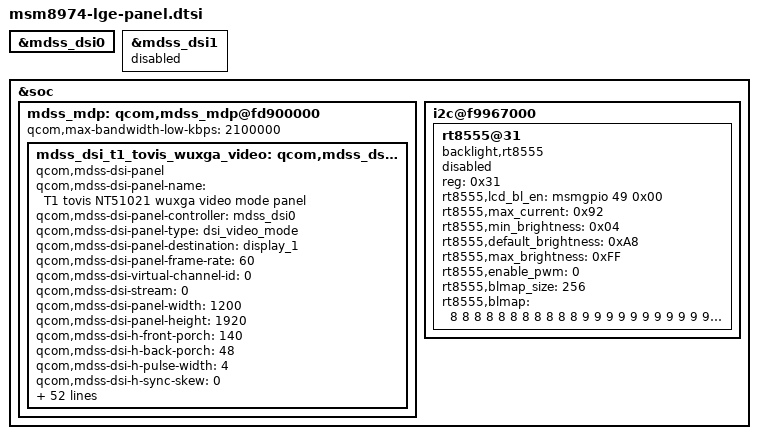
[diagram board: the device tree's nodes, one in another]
/* Copyright (c) 2013, LGE Electronics. All rights reserved.
 *
 * This program is free software; you can redistribute it and/or modify
 * it under the terms of the GNU General Public License version 2 and
 * only version 2 as published by the Free Software Foundation.
 *
 * This program is distributed in the hope that it will be useful,
 * but WITHOUT ANY WARRANTY; without even the implied warranty of
 * MERCHANTABILITY or FITNESS FOR A PARTICULAR PURPOSE.  See the
 * GNU General Public License for more details.
 */

/*---------------------------------------------------------------------------
 * This file is autogenerated file using gcdb parser. Please do not edit it.
 * Update input XML file to add a new entry or update variable in this file
 * VERSION = "1.0"
 *---------------------------------------------------------------------------*/

&mdss_dsi0 {
	/delete-node/ qcom,platform-supply-entry1;
};

&mdss_dsi1 {
	status = "disable";
};

&soc {
	mdss_mdp: qcom,mdss_mdp@fd900000 {
		qcom,max-bandwidth-low-kbps = <2100000>;
	};
};

&mdss_mdp {
		/delete-property/ qcom,mdss-ad-off;

mdss_dsi_t1_tovis_wuxga_video: qcom,mdss_dsi_tovis_nt51021_t1_wuxga_video {
		compatible = "qcom,mdss-dsi-panel";
		qcom,mdss-dsi-panel-name = "T1 tovis NT51021 wuxga video mode panel";
		qcom,mdss-dsi-panel-controller = <&mdss_dsi0>;
		qcom,mdss-dsi-panel-type = "dsi_video_mode";
		qcom,mdss-dsi-panel-destination = "display_1";
		qcom,mdss-dsi-panel-frame-rate = <60>;
		qcom,mdss-dsi-virtual-channel-id = <0>;
		qcom,mdss-dsi-stream = <0>;
		qcom,mdss-dsi-panel-width = <1200>;
		qcom,mdss-dsi-panel-height = <1920>;
		qcom,mdss-dsi-h-front-porch = <140>;
		qcom,mdss-dsi-h-back-porch = <48>;
		qcom,mdss-dsi-h-pulse-width = <4>;
		qcom,mdss-dsi-h-sync-skew = <0>;
		qcom,mdss-dsi-v-back-porch = <14>;
		qcom,mdss-dsi-v-front-porch = <16>;
		qcom,mdss-dsi-v-pulse-width = <1>;
		qcom,mdss-dsi-h-left-border = <0>;
		qcom,mdss-dsi-h-right-border = <0>;
		qcom,mdss-dsi-v-top-border = <0>;
		qcom,mdss-dsi-v-bottom-border = <0>;
		qcom,mdss-dsi-bpp = <24>;
		qcom,mdss-dsi-color-order = "rgb_swap_rgb";
		qcom,mdss-dsi-underflow-color = <0xff>;
		qcom,mdss-dsi-border-color = <0>;
		qcom,mdss-dsi-reset-sequence = <1 5>;
		qcom,cont-splash-enabled;
		qcom,mdss-dsi-lane-hs = <1>;
		qcom,mdss-dsi-on-command = [
		15 01 00 00 00 00 02 83 00
		15 01 00 00 00 00 02 84 00
		15 01 00 00 00 00 02 97 C0  // Set terminal resistor to 75 ohm
		15 01 00 00 00 00 02 8C 8E  // Change HAVDD , V1/V14 , Gamma to register control
		15 01 00 00 00 00 02 FA 12  // Set HAVDD = 4.8V
		15 01 00 00 01 00 02 FD 1B  // Set V1 = 9.4V , V14 = 0.2V
		15 01 00 00 00 00 02 C4 12  // Set STV rising timing
		15 01 00 00 00 00 02 C5 77  // Set STV falling timing
		15 01 00 00 00 00 02 C6 12  // Set GCLK rising timing
		15 01 00 00 00 00 02 C7 77  // Set GCLK falling timing
		15 01 00 00 00 00 02 83 AA
		15 01 00 00 00 00 02 84 11
		15 01 00 00 00 00 02 A9 4B  // Set MIPI Rx ability to solve data loss
		15 01 00 00 00 00 02 A0 36  // Set Slave IC of MIPI D0/D1 lane delay 100ps
		15 01 00 00 00 00 02 A1 3F  // Set Slave IC of MIPI D2/D3 lane delay 150ps
		15 01 00 00 00 00 02 A2 2D  // Set Master IC of MIPI D0/D1 lane delay 50ps
		15 01 00 00 00 00 02 A3 36  // Set Master IC of MIPI D2/D3 lane delay 100ps
		//----R Gamma Register----
		15 01 00 00 00 00 02 83 AA
		15 01 00 00 00 00 02 84 11
		15 01 00 00 00 00 02 C0 12
		15 01 00 00 00 00 02 C1 12
		15 01 00 00 00 00 02 C2 25
		15 01 00 00 00 00 02 C3 36
		15 01 00 00 00 00 02 C4 42
		15 01 00 00 00 00 02 C5 4B
		15 01 00 00 00 00 02 C6 57
		15 01 00 00 00 00 02 C7 5B
		15 01 00 00 00 00 02 C8 66
		15 01 00 00 00 00 02 C9 DB
		15 01 00 00 00 00 02 CA DF
		15 01 00 00 00 00 02 CB F5
		15 01 00 00 00 00 02 CC FE
		15 01 00 00 00 00 02 CD FC
		15 01 00 00 00 00 02 CE F7
		15 01 00 00 00 00 02 CF F9
		15 01 00 00 00 00 02 D0 FB
		15 01 00 00 00 00 02 D1 0A
		15 01 00 00 00 00 02 D2 1F
		15 01 00 00 00 00 02 D3 40
		15 01 00 00 00 00 02 D4 4A
		15 01 00 00 00 00 02 D5 AE
		15 01 00 00 00 00 02 D6 B0
		15 01 00 00 00 00 02 D7 BB
		15 01 00 00 00 00 02 D8 C5
		15 01 00 00 00 00 02 D9 CE
		15 01 00 00 00 00 02 DA D8
		15 01 00 00 00 00 02 DB E7
		15 01 00 00 00 00 02 DC F0
		15 01 00 00 00 00 02 DD FF
		15 01 00 00 00 00 02 DE 00
		15 01 00 00 00 00 02 DF 2F
		15 01 00 00 00 00 02 E0 12
		15 01 00 00 00 00 02 E1 12
		15 01 00 00 00 00 02 E2 25
		15 01 00 00 00 00 02 E3 36
		15 01 00 00 00 00 02 E4 42
		15 01 00 00 00 00 02 E5 4B
		15 01 00 00 00 00 02 E6 57
		15 01 00 00 00 00 02 E7 5B
		15 01 00 00 00 00 02 E8 66
		15 01 00 00 00 00 02 E9 DB
		15 01 00 00 00 00 02 EA DF
		15 01 00 00 00 00 02 EB F5
		15 01 00 00 00 00 02 EC FE
		15 01 00 00 00 00 02 ED FC
		15 01 00 00 00 00 02 EE F7
		15 01 00 00 00 00 02 EF F9
		15 01 00 00 00 00 02 F0 FB
		15 01 00 00 00 00 02 F1 0A
		15 01 00 00 00 00 02 F2 1F
		15 01 00 00 00 00 02 F3 40
		15 01 00 00 00 00 02 F4 4A
		15 01 00 00 00 00 02 F5 AE
		15 01 00 00 00 00 02 F6 B0
		15 01 00 00 00 00 02 F7 BB
		15 01 00 00 00 00 02 F8 C5
		15 01 00 00 00 00 02 F9 CE
		15 01 00 00 00 00 02 FA D8
		15 01 00 00 00 00 02 FB E7
		15 01 00 00 00 00 02 FC F0
		15 01 00 00 00 00 02 FD FF
		15 01 00 00 00 00 02 FE 00
		15 01 00 00 00 00 02 FF 2F
		//----G Gamma Register----
		15 01 00 00 00 00 02 83 BB
		15 01 00 00 00 00 02 84 22
		15 01 00 00 00 00 02 C0 12
		15 01 00 00 00 00 02 C1 12
		15 01 00 00 00 00 02 C2 25
		15 01 00 00 00 00 02 C3 36
		15 01 00 00 00 00 02 C4 42
		15 01 00 00 00 00 02 C5 4B
		15 01 00 00 00 00 02 C6 57
		15 01 00 00 00 00 02 C7 5B
		15 01 00 00 00 00 02 C8 66
		15 01 00 00 00 00 02 C9 DB
		15 01 00 00 00 00 02 CA DF
		15 01 00 00 00 00 02 CB F5
		15 01 00 00 00 00 02 CC FE
		15 01 00 00 00 00 02 CD FC
		15 01 00 00 00 00 02 CE F7
		15 01 00 00 00 00 02 CF F9
		15 01 00 00 00 00 02 D0 FB
		15 01 00 00 00 00 02 D1 0A
		15 01 00 00 00 00 02 D2 1F
		15 01 00 00 00 00 02 D3 40
		15 01 00 00 00 00 02 D4 4A
		15 01 00 00 00 00 02 D5 AE
		15 01 00 00 00 00 02 D6 B0
		15 01 00 00 00 00 02 D7 BB
		15 01 00 00 00 00 02 D8 C5
		15 01 00 00 00 00 02 D9 CE
		15 01 00 00 00 00 02 DA D8
		15 01 00 00 00 00 02 DB E7
		15 01 00 00 00 00 02 DC F0
		15 01 00 00 00 00 02 DD FF
		15 01 00 00 00 00 02 DE 00
		15 01 00 00 00 00 02 DF 2F
		15 01 00 00 00 00 02 E0 12
		15 01 00 00 00 00 02 E1 12
		15 01 00 00 00 00 02 E2 25
		15 01 00 00 00 00 02 E3 36
		15 01 00 00 00 00 02 E4 42
		15 01 00 00 00 00 02 E5 4B
		15 01 00 00 00 00 02 E6 57
		15 01 00 00 00 00 02 E7 5B
		15 01 00 00 00 00 02 E8 66
		15 01 00 00 00 00 02 E9 DB
		15 01 00 00 00 00 02 EA DF
		15 01 00 00 00 00 02 EB F5
		15 01 00 00 00 00 02 EC FE
		15 01 00 00 00 00 02 ED FC
		15 01 00 00 00 00 02 EE F7
		15 01 00 00 00 00 02 EF F9
		15 01 00 00 00 00 02 F0 FB
		15 01 00 00 00 00 02 F1 0A
		15 01 00 00 00 00 02 F2 1F
		15 01 00 00 00 00 02 F3 40
		15 01 00 00 00 00 02 F4 4A
		15 01 00 00 00 00 02 F5 AE
		15 01 00 00 00 00 02 F6 B0
		15 01 00 00 00 00 02 F7 BB
		15 01 00 00 00 00 02 F8 C5
		15 01 00 00 00 00 02 F9 CE
		15 01 00 00 00 00 02 FA D8
		15 01 00 00 00 00 02 FB E7
		15 01 00 00 00 00 02 FC F0
		15 01 00 00 00 00 02 FD FF
		15 01 00 00 00 00 02 FE 00
		15 01 00 00 00 00 02 FF 2F
		//----B Gamma Register----
		15 01 00 00 00 00 02 83 CC
		15 01 00 00 00 00 02 84 33
		15 01 00 00 00 00 02 C0 12
		15 01 00 00 00 00 02 C1 12
		15 01 00 00 00 00 02 C2 25
		15 01 00 00 00 00 02 C3 36
		15 01 00 00 00 00 02 C4 42
		15 01 00 00 00 00 02 C5 4B
		15 01 00 00 00 00 02 C6 57
		15 01 00 00 00 00 02 C7 5B
		15 01 00 00 00 00 02 C8 66
		15 01 00 00 00 00 02 C9 DB
		15 01 00 00 00 00 02 CA DF
		15 01 00 00 00 00 02 CB F5
		15 01 00 00 00 00 02 CC FE
		15 01 00 00 00 00 02 CD FC
		15 01 00 00 00 00 02 CE F7
		15 01 00 00 00 00 02 CF F9
		15 01 00 00 00 00 02 D0 FB
		15 01 00 00 00 00 02 D1 0A
		15 01 00 00 00 00 02 D2 1F
		15 01 00 00 00 00 02 D3 40
		15 01 00 00 00 00 02 D4 4A
		15 01 00 00 00 00 02 D5 AE
		15 01 00 00 00 00 02 D6 B0
		15 01 00 00 00 00 02 D7 BB
		15 01 00 00 00 00 02 D8 C5
		15 01 00 00 00 00 02 D9 CE
		15 01 00 00 00 00 02 DA D8
		15 01 00 00 00 00 02 DB E7
		15 01 00 00 00 00 02 DC F0
		15 01 00 00 00 00 02 DD FF
		15 01 00 00 00 00 02 DE 00
		15 01 00 00 00 00 02 DF 2F
		15 01 00 00 00 00 02 E0 12
		15 01 00 00 00 00 02 E1 12
		15 01 00 00 00 00 02 E2 25
		15 01 00 00 00 00 02 E3 36
		15 01 00 00 00 00 02 E4 42
		15 01 00 00 00 00 02 E5 4B
		15 01 00 00 00 00 02 E6 57
		15 01 00 00 00 00 02 E7 5B
		15 01 00 00 00 00 02 E8 66
		15 01 00 00 00 00 02 E9 DB
		15 01 00 00 00 00 02 EA DF
		15 01 00 00 00 00 02 EB F5
		15 01 00 00 00 00 02 EC FE
		15 01 00 00 00 00 02 ED FC
		15 01 00 00 00 00 02 EE F7
		15 01 00 00 00 00 02 EF F9
		15 01 00 00 00 00 02 F0 FB
		15 01 00 00 00 00 02 F1 0A
		15 01 00 00 00 00 02 F2 1F
		15 01 00 00 00 00 02 F3 40
		15 01 00 00 00 00 02 F4 4A
		15 01 00 00 00 00 02 F5 AE
		15 01 00 00 00 00 02 F6 B0
		15 01 00 00 00 00 02 F7 BB
		15 01 00 00 00 00 02 F8 C5
		15 01 00 00 00 00 02 F9 CE
		15 01 00 00 00 00 02 FA D8
		15 01 00 00 00 00 02 FB E7
		15 01 00 00 00 00 02 FC F0
		15 01 00 00 00 00 02 FD FF
		15 01 00 00 00 00 02 FE 00
		15 01 00 00 00 00 02 FF 2F
		];

		qcom,mdss-dsi-off-command = [
		05 01 00 00 64 00 02 10 00
		];

		qcom,panel-charging-time-on-command = [
		15 01 00 00 00 00 02 83 00
		15 01 00 00 00 00 02 84 00
		15 01 00 00 00 00 02 C7 A6
		];

		qcom,panel-charging-time-off-command = [
		15 01 00 00 00 00 02 83 00
		15 01 00 00 00 00 02 84 00
		15 01 00 00 00 00 02 C7 77
		];

		qcom,panel-reader-mode-initial-on-command = [
		15 01 00 00 00 00 02 83 00
		15 01 00 00 00 00 02 84 00
		15 01 00 00 00 00 02 97 C0
		15 01 00 00 00 00 02 8C 8E
		15 01 00 00 00 00 02 FA 12
		15 01 00 00 01 00 02 FD 1B
		15 01 00 00 00 00 02 C4 12
		15 01 00 00 00 00 02 C5 77
		15 01 00 00 00 00 02 C6 12
		15 01 00 00 00 00 02 C7 77
		15 01 00 00 00 00 02 83 AA
		15 01 00 00 00 00 02 84 11
		15 00 00 00 00 00 02 A9 4B
		15 01 00 00 00 00 02 A0 36
		15 01 00 00 00 00 02 A1 3F
		15 01 00 00 00 00 02 A2 2D
		15 01 00 00 00 00 02 A3 36
		//----R Gamma Register----
		15 01 00 00 00 00 02 83 AA
		15 01 00 00 00 00 02 84 11
		15 01 00 00 00 00 02 C0 00
		15 01 00 00 00 00 02 C1 0A
		15 01 00 00 00 00 02 C2 0F
		15 01 00 00 00 00 02 C3 17
		15 01 00 00 00 00 02 C4 21
		15 01 00 00 00 00 02 C5 31
		15 01 00 00 00 00 02 C6 42
		15 01 00 00 00 00 02 C7 4D
		15 01 00 00 00 00 02 C8 55
		15 01 00 00 00 00 02 C9 B0
		15 01 00 00 00 00 02 CA B8
		15 01 00 00 00 00 02 CB D4
		15 01 00 00 00 00 02 CC E2
		15 01 00 00 00 00 02 CD EA
		15 01 00 00 00 00 02 CE ED
		15 01 00 00 00 00 02 CF EF
		15 01 00 00 00 00 02 D0 F7
		15 01 00 00 00 00 02 D1 0E
		15 01 00 00 00 00 02 D2 24
		15 01 00 00 00 00 02 D3 46
		15 01 00 00 00 00 02 D4 50
		15 01 00 00 00 00 02 D5 B1
		15 01 00 00 00 00 02 D6 B8
		15 01 00 00 00 00 02 D7 C0
		15 01 00 00 00 00 02 D8 C9
		15 01 00 00 00 00 02 D9 D2
		15 01 00 00 00 00 02 DA DD
		15 01 00 00 00 00 02 DB E9
		15 01 00 00 00 00 02 DC F7
		15 01 00 00 00 00 02 DD FF
		15 01 00 00 00 00 02 DE 00
		15 01 00 00 00 00 02 DF 0F
		15 01 00 00 00 00 02 E0 00
		15 01 00 00 00 00 02 E1 0A
		15 01 00 00 00 00 02 E2 0F
		15 01 00 00 00 00 02 E3 17
		15 01 00 00 00 00 02 E4 21
		15 01 00 00 00 00 02 E5 31
		15 01 00 00 00 00 02 E6 42
		15 01 00 00 00 00 02 E7 4D
		15 01 00 00 00 00 02 E8 55
		15 01 00 00 00 00 02 E9 B0
		15 01 00 00 00 00 02 EA B8
		15 01 00 00 00 00 02 EB D4
		15 01 00 00 00 00 02 EC E2
		15 01 00 00 00 00 02 ED EA
		15 01 00 00 00 00 02 EE ED
		15 01 00 00 00 00 02 EF EF
		15 01 00 00 00 00 02 F0 F7
		15 01 00 00 00 00 02 F1 0E
		15 01 00 00 00 00 02 F2 24
		15 01 00 00 00 00 02 F3 46
		15 01 00 00 00 00 02 F4 50
		15 01 00 00 00 00 02 F5 B1
		15 01 00 00 00 00 02 F6 B8
		15 01 00 00 00 00 02 F7 C0
		15 01 00 00 00 00 02 F8 C9
		15 01 00 00 00 00 02 F9 D2
		15 01 00 00 00 00 02 FA DD
		15 01 00 00 00 00 02 FB E9
		15 01 00 00 00 00 02 FC F7
		15 01 00 00 00 00 02 FD FF
		15 01 00 00 00 00 02 FE 00
		15 01 00 00 00 00 02 FF 0F
		//----G Gamma Register----
		15 01 00 00 00 00 02 83 BB
		15 01 00 00 00 00 02 84 22
		15 01 00 00 00 00 02 C0 00
		15 01 00 00 00 00 02 C1 0A
		15 01 00 00 00 00 02 C2 10
		15 01 00 00 00 00 02 C3 18
		15 01 00 00 00 00 02 C4 21
		15 01 00 00 00 00 02 C5 2A
		15 01 00 00 00 00 02 C6 34
		15 01 00 00 00 00 02 C7 3D
		15 01 00 00 00 00 02 C8 45
		15 01 00 00 00 00 02 C9 9A
		15 01 00 00 00 00 02 CA A6
		15 01 00 00 00 00 02 CB C0
		15 01 00 00 00 00 02 CC CB
		15 01 00 00 00 00 02 CD D2
		15 01 00 00 00 00 02 CE D2
		15 01 00 00 00 00 02 CF D4
		15 01 00 00 00 00 02 D0 D4
		15 01 00 00 00 00 02 D1 DE
		15 01 00 00 00 00 02 D2 EA
		15 01 00 00 00 00 02 D3 FB
		15 01 00 00 00 00 02 D4 F7
		15 01 00 00 00 00 02 D5 7B
		15 01 00 00 00 00 02 D6 7F
		15 01 00 00 00 00 02 D7 83
		15 01 00 00 00 00 02 D8 87
		15 01 00 00 00 00 02 D9 8C
		15 01 00 00 00 00 02 DA 90
		15 01 00 00 00 00 02 DB 95
		15 01 00 00 00 00 02 DC 9A
		15 01 00 00 00 00 02 DD 9D
		15 01 00 00 00 00 02 DE 00
		15 01 00 00 00 00 02 DF 00
		15 01 00 00 00 00 02 E0 00
		15 01 00 00 00 00 02 E1 0A
		15 01 00 00 00 00 02 E2 10
		15 01 00 00 00 00 02 E3 18
		15 01 00 00 00 00 02 E4 21
		15 01 00 00 00 00 02 E5 2A
		15 01 00 00 00 00 02 E6 34
		15 01 00 00 00 00 02 E7 3D
		15 01 00 00 00 00 02 E8 45
		15 01 00 00 00 00 02 E9 9A
		15 01 00 00 00 00 02 EA A6
		15 01 00 00 00 00 02 EB C0
		15 01 00 00 00 00 02 EC CB
		15 01 00 00 00 00 02 ED D2
		15 01 00 00 00 00 02 EE D2
		15 01 00 00 00 00 02 EF D4
		15 01 00 00 00 00 02 F0 D4
		15 01 00 00 00 00 02 F1 DE
		15 01 00 00 00 00 02 F2 EA
		15 01 00 00 00 00 02 F3 FB
		15 01 00 00 00 00 02 F4 F7
		15 01 00 00 00 00 02 F5 7B
		15 01 00 00 00 00 02 F6 7F
		15 01 00 00 00 00 02 F7 83
		15 01 00 00 00 00 02 F8 87
		15 01 00 00 00 00 02 F9 8C
		15 01 00 00 00 00 02 FA 90
		15 01 00 00 00 00 02 FB 95
		15 01 00 00 00 00 02 FC 9A
		15 01 00 00 00 00 02 FD 9D
		15 01 00 00 00 00 02 FE 00
		15 01 00 00 00 00 02 FF 00
		//----B Gamma Register----
		15 01 00 00 00 00 02 83 CC
		15 01 00 00 00 00 02 84 33
		15 01 00 00 00 00 02 C0 00
		15 01 00 00 00 00 02 C1 06
		15 01 00 00 00 00 02 C2 09
		15 01 00 00 00 00 02 C3 12
		15 01 00 00 00 00 02 C4 17
		15 01 00 00 00 00 02 C5 18
		15 01 00 00 00 00 02 C6 1A
		15 01 00 00 00 00 02 C7 1C
		15 01 00 00 00 00 02 C8 24
		15 01 00 00 00 00 02 C9 79
		15 01 00 00 00 00 02 CA 8F
		15 01 00 00 00 00 02 CB B1
		15 01 00 00 00 00 02 CC BF
		15 01 00 00 00 00 02 CD C4
		15 01 00 00 00 00 02 CE C2
		15 01 00 00 00 00 02 CF C4
		15 01 00 00 00 00 02 D0 C1
		15 01 00 00 00 00 02 D1 C3
		15 01 00 00 00 00 02 D2 C9
		15 01 00 00 00 00 02 D3 D2
		15 01 00 00 00 00 02 D4 C9
		15 01 00 00 00 00 02 D5 60
		15 01 00 00 00 00 02 D6 63
		15 01 00 00 00 00 02 D7 66
		15 01 00 00 00 00 02 D8 6A
		15 01 00 00 00 00 02 D9 6D
		15 01 00 00 00 00 02 DA 70
		15 01 00 00 00 00 02 DB 74
		15 01 00 00 00 00 02 DC 77
		15 01 00 00 00 00 02 DD 79
		15 01 00 00 00 00 02 DE 00
		15 01 00 00 00 00 02 DF 00
		15 01 00 00 00 00 02 E0 00
		15 01 00 00 00 00 02 E1 06
		15 01 00 00 00 00 02 E2 09
		15 01 00 00 00 00 02 E3 12
		15 01 00 00 00 00 02 E4 17
		15 01 00 00 00 00 02 E5 18
		15 01 00 00 00 00 02 E6 1A
		15 01 00 00 00 00 02 E7 1C
		15 01 00 00 00 00 02 E8 24
		15 01 00 00 00 00 02 E9 79
		15 01 00 00 00 00 02 EA 8F
		15 01 00 00 00 00 02 EB B1
		15 01 00 00 00 00 02 EC BF
		15 01 00 00 00 00 02 ED C4
		15 01 00 00 00 00 02 EE C2
		15 01 00 00 00 00 02 EF C4
		15 01 00 00 00 00 02 F0 C1
		15 01 00 00 00 00 02 F1 C3
		15 01 00 00 00 00 02 F2 C9
		15 01 00 00 00 00 02 F3 D2
		15 01 00 00 00 00 02 F4 C9
		15 01 00 00 00 00 02 F5 60
		15 01 00 00 00 00 02 F6 63
		15 01 00 00 00 00 02 F7 66
		15 01 00 00 00 00 02 F8 6A
		15 01 00 00 00 00 02 F9 6D
		15 01 00 00 00 00 02 FA 70
		15 01 00 00 00 00 02 FB 74
		15 01 00 00 00 00 02 FC 77
		15 01 00 00 00 00 02 FD 79
		15 01 00 00 00 00 02 FE 00
		15 01 00 00 00 00 02 FF 00
		];

		qcom,panel-reader-mode-on-command = [
		//----B Gamma Register----
		15 00 00 00 00 00 02 83 CC
		15 00 00 00 00 00 02 84 33
		15 00 00 00 00 00 02 C0 00
		15 00 00 00 00 00 02 C1 06
		15 00 00 00 00 00 02 C2 09
		15 00 00 00 00 00 02 C3 12
		15 00 00 00 00 00 02 C4 17
		15 00 00 00 00 00 02 C5 18
		15 00 00 00 00 00 02 C6 1A
		15 00 00 00 00 00 02 C7 1C
		15 00 00 00 00 00 02 C8 24
		15 00 00 00 00 00 02 C9 79
		15 00 00 00 00 00 02 CA 8F
		15 00 00 00 00 00 02 CB B1
		15 00 00 00 00 00 02 CC BF
		15 01 00 00 00 00 02 CD C4
		15 00 00 00 00 00 02 CE C2
		15 00 00 00 00 00 02 CF C4
		15 00 00 00 00 00 02 D0 C1
		15 00 00 00 00 00 02 D1 C3
		15 00 00 00 00 00 02 D2 C9
		15 00 00 00 00 00 02 D3 D2
		15 00 00 00 00 00 02 D4 C9
		15 00 00 00 00 00 02 D5 60
		15 00 00 00 00 00 02 D6 63
		15 00 00 00 00 00 02 D7 66
		15 00 00 00 00 00 02 D8 6A
		15 00 00 00 00 00 02 D9 6D
		15 00 00 00 00 00 02 DA 70
		15 00 00 00 00 00 02 DB 74
		15 00 00 00 00 00 02 DC 77
		15 00 00 00 00 00 02 DD 79
		15 00 00 00 00 00 02 DE 00
		15 00 00 00 00 00 02 DF 00
		15 00 00 00 00 00 02 E0 00
		15 01 00 00 00 00 02 E1 06
		15 00 00 00 00 00 02 E2 09
		15 00 00 00 00 00 02 E3 12
		15 00 00 00 00 00 02 E4 17
		15 00 00 00 00 00 02 E5 18
		15 00 00 00 00 00 02 E6 1A
		15 00 00 00 00 00 02 E7 1C
		15 00 00 00 00 00 02 E8 24
		15 00 00 00 00 00 02 E9 79
		15 00 00 00 00 00 02 EA 8F
		15 00 00 00 00 00 02 EB B1
		15 00 00 00 00 00 02 EC BF
		15 00 00 00 00 00 02 ED C4
		15 00 00 00 00 00 02 EE C2
		15 00 00 00 00 00 02 EF C4
		15 00 00 00 00 00 02 F0 C1
		15 00 00 00 00 00 02 F1 C3
		15 00 00 00 00 00 02 F2 C9
		15 00 00 00 00 00 02 F3 D2
		15 00 00 00 00 00 02 F4 C9
		15 01 00 00 00 00 02 F5 60
		15 00 00 00 00 00 02 F6 63
		15 00 00 00 00 00 02 F7 66
		15 00 00 00 00 00 02 F8 6A
		15 00 00 00 00 00 02 F9 6D
		15 00 00 00 00 00 02 FA 70
		15 00 00 00 00 00 02 FB 74
		15 00 00 00 00 00 02 FC 77
		15 00 00 00 00 00 02 FD 79
		15 00 00 00 00 00 02 FE 00
		15 00 00 00 00 00 02 FF 00
		//----G Gamma Register----
		15 00 00 00 00 00 02 83 BB
		15 01 00 00 00 00 02 84 22
		15 00 00 00 00 00 02 C0 00
		15 00 00 00 00 00 02 C1 0A
		15 00 00 00 00 00 02 C2 10
		15 00 00 00 00 00 02 C3 18
		15 00 00 00 00 00 02 C4 21
		15 00 00 00 00 00 02 C5 2A
		15 00 00 00 00 00 02 C6 34
		15 00 00 00 00 00 02 C7 3D
		15 00 00 00 00 00 02 C8 45
		15 00 00 00 00 00 02 C9 9A
		15 01 00 00 00 00 02 CA A6
		15 00 00 00 00 00 02 CB C0
		15 00 00 00 00 00 02 CC CB
		15 00 00 00 00 00 02 CD D2
		15 00 00 00 00 00 02 CE D2
		15 00 00 00 00 00 02 CF D4
		15 00 00 00 00 00 02 D0 D4
		15 00 00 00 00 00 02 D1 DE
		15 00 00 00 00 00 02 D2 EA
		15 00 00 00 00 00 02 D3 FB
		15 00 00 00 00 00 02 D4 F7
		15 00 00 00 00 00 02 D5 7B
		15 00 00 00 00 00 02 D6 7F
		15 00 00 00 00 00 02 D7 83
		15 00 00 00 00 00 02 D8 87
		15 00 00 00 00 00 02 D9 8C
		15 00 00 00 00 00 02 DA 90
		15 00 00 00 00 00 02 DB 95
		15 00 00 00 00 00 02 DC 9A
		15 00 00 00 00 00 02 DD 9D
		15 00 00 00 00 00 02 DE 00
		15 00 00 00 00 00 02 DF 00
		15 00 00 00 00 00 02 E0 00
		15 00 00 00 00 00 02 E1 0A
		15 01 00 00 00 00 02 E2 10
		15 00 00 00 00 00 02 E3 18
		15 00 00 00 00 00 02 E4 21
		15 00 00 00 00 00 02 E5 2A
		15 00 00 00 00 00 02 E6 34
		15 00 00 00 00 00 02 E7 3D
		15 00 00 00 00 00 02 E8 45
		15 00 00 00 00 00 02 E9 9A
		15 00 00 00 00 00 02 EA A6
		15 00 00 00 00 00 02 EB C0
		15 01 00 00 00 00 02 EC CB
		15 00 00 00 00 00 02 ED D2
		15 00 00 00 00 00 02 EE D2
		15 00 00 00 00 00 02 EF D4
		15 00 00 00 00 00 02 F0 D4
		15 00 00 00 00 00 02 F1 DE
		15 00 00 00 00 00 02 F2 EA
		15 00 00 00 00 00 02 F3 FB
		15 00 00 00 00 00 02 F4 F7
		15 00 00 00 00 00 02 F5 7B
		15 00 00 00 00 00 02 F6 7F
		15 00 00 00 00 00 02 F7 83
		15 00 00 00 00 00 02 F8 87
		15 00 00 00 00 00 02 F9 8C
		15 00 00 00 00 00 02 FA 90
		15 00 00 00 00 00 02 FB 95
		15 00 00 00 00 00 02 FC 9A
		15 00 00 00 00 00 02 FD 9D
		15 00 00 00 00 00 02 FE 00
		15 00 00 00 00 00 02 FF 00
		//----R Gamma Register----
		15 00 00 00 00 00 02 83 AA
		15 01 00 00 00 00 02 84 11
		15 00 00 00 00 00 02 C0 00
		15 00 00 00 00 00 02 C1 0A
		15 00 00 00 00 00 02 C2 0F
		15 00 00 00 00 00 02 C3 17
		15 00 00 00 00 00 02 C4 21
		15 00 00 00 00 00 02 C5 31
		15 00 00 00 00 00 02 C6 42
		15 00 00 00 00 00 02 C7 4D
		15 00 00 00 00 00 02 C8 55
		15 00 00 00 00 00 02 C9 B0
		15 00 00 00 00 00 02 CA B8
		15 00 00 00 00 00 02 CB D4
		15 00 00 00 00 00 02 CC E2
		15 00 00 00 00 00 02 CD EA
		15 00 00 00 00 00 02 CE ED
		15 00 00 00 00 00 02 CF EF
		15 00 00 00 00 00 02 D0 F7
		15 00 00 00 00 00 02 D1 0E
		15 00 00 00 00 00 02 D2 24
		15 00 00 00 00 00 02 D3 46
		15 00 00 00 00 00 02 D4 50
		15 00 00 00 00 00 02 D5 B1
		15 00 00 00 00 00 02 D6 B8
		15 01 00 00 00 00 02 D7 C0
		15 00 00 00 00 00 02 D8 C9
		15 00 00 00 00 00 02 D9 D2
		15 00 00 00 00 00 02 DA DD
		15 00 00 00 00 00 02 DB E9
		15 00 00 00 00 00 02 DC F7
		15 00 00 00 00 00 02 DD FF
		15 00 00 00 00 00 02 DE 00
		15 00 00 00 00 00 02 DF 0F
		15 00 00 00 00 00 02 E0 00
		15 00 00 00 00 00 02 E1 0A
		15 00 00 00 00 00 02 E2 0F
		15 00 00 00 00 00 02 E3 17
		15 00 00 00 00 00 02 E4 21
		15 00 00 00 00 00 02 E5 31
		15 00 00 00 00 00 02 E6 42
		15 00 00 00 00 00 02 E7 4D
		15 00 00 00 00 00 02 E8 55
		15 00 00 00 00 00 02 E9 B0
		15 00 00 00 00 00 02 EA B8
		15 01 00 00 00 00 02 EB D4
		15 00 00 00 00 00 02 EC E2
		15 00 00 00 00 00 02 ED EA
		15 00 00 00 00 00 02 EE ED
		15 00 00 00 00 00 02 EF EF
		15 00 00 00 00 00 02 F0 F7
		15 00 00 00 00 00 02 F1 0E
		15 00 00 00 00 00 02 F2 24
		15 00 00 00 00 00 02 F3 46
		15 00 00 00 00 00 02 F4 50
		15 00 00 00 00 00 02 F5 B1
		15 00 00 00 00 00 02 F6 B8
		15 00 00 00 00 00 02 F7 C0
		15 00 00 00 00 00 02 F8 C9
		15 00 00 00 00 00 02 F9 D2
		15 00 00 00 00 00 02 FA DD
		15 00 00 00 00 00 02 FB E9
		15 00 00 00 00 00 02 FC F7
		15 00 00 00 00 00 02 FD FF
		15 00 00 00 00 00 02 FE 00
		15 01 00 00 00 00 02 FF 0F
		];

		qcom,panel-reader-mode-off-command = [
		//----B Gamma Register----
		15 00 00 00 00 00 02 83 CC
		15 00 00 00 00 00 02 84 33
		15 00 00 00 00 00 02 C0 12
		15 00 00 00 00 00 02 C1 12
		15 00 00 00 00 00 02 C2 25
		15 00 00 00 00 00 02 C3 36
		15 00 00 00 00 00 02 C4 42
		15 00 00 00 00 00 02 C5 4B
		15 00 00 00 00 00 02 C6 57
		15 00 00 00 00 00 02 C7 5B
		15 00 00 00 00 00 02 C8 66
		15 00 00 00 00 00 02 C9 DB
		15 00 00 00 00 00 02 CA DF
		15 00 00 00 00 00 02 CB F5
		15 00 00 00 00 00 02 CC FE
		15 00 00 00 00 00 02 CD FC
		15 00 00 00 00 00 02 CE F7
		15 00 00 00 00 00 02 CF F9
		15 00 00 00 00 00 02 D0 FB
		15 01 00 00 00 00 02 D1 0A
		15 00 00 00 00 00 02 D2 1F
		15 00 00 00 00 00 02 D3 40
		15 00 00 00 00 00 02 D4 4A
		15 00 00 00 00 00 02 D5 AE
		15 00 00 00 00 00 02 D6 B0
		15 00 00 00 00 00 02 D7 BB
		15 00 00 00 00 00 02 D8 C5
		15 00 00 00 00 00 02 D9 CE
		15 00 00 00 00 00 02 DA D8
		15 00 00 00 00 00 02 DB E7
		15 01 00 00 00 00 02 DC F0
		15 00 00 00 00 00 02 DD FF
		15 00 00 00 00 00 02 DE 00
		15 00 00 00 00 00 02 DF 2F
		15 00 00 00 00 00 02 E0 12
		15 00 00 00 00 00 02 E1 12
		15 00 00 00 00 00 02 E2 25
		15 00 00 00 00 00 02 E3 36
		15 00 00 00 00 00 02 E4 42
		15 00 00 00 00 00 02 E5 4B
		15 00 00 00 00 00 02 E6 57
		15 00 00 00 00 00 02 E7 5B
		15 00 00 00 00 00 02 E8 66
		15 00 00 00 00 00 02 E9 DB
		15 00 00 00 00 00 02 EA DF
		15 00 00 00 00 00 02 EB F5
		15 00 00 00 00 00 02 EC FE
		15 00 00 00 00 00 02 ED FC
		15 00 00 00 00 00 02 EE F7
		15 00 00 00 00 00 02 EF F9
		15 00 00 00 00 00 02 F0 FB
		15 01 00 00 00 00 02 F1 0A
		15 00 00 00 00 00 02 F2 1F
		15 00 00 00 00 00 02 F3 40
		15 00 00 00 00 00 02 F4 4A
		15 00 00 00 00 00 02 F5 AE
		15 00 00 00 00 00 02 F6 B0
		15 00 00 00 00 00 02 F7 BB
		15 00 00 00 00 00 02 F8 C5
		15 00 00 00 00 00 02 F9 CE
		15 00 00 00 00 00 02 FA D8
		15 00 00 00 00 00 02 FB E7
		15 00 00 00 00 00 02 FC F0
		15 00 00 00 00 00 02 FD FF
		15 00 00 00 00 00 02 FE 00
		15 00 00 00 00 00 02 FF 2F
		//----G Gamma Register----
		15 00 00 00 00 00 02 83 BB
		15 01 00 00 00 00 02 84 22
		15 00 00 00 00 00 02 C0 12
		15 00 00 00 00 00 02 C1 12
		15 00 00 00 00 00 02 C2 25
		15 00 00 00 00 00 02 C3 36
		15 00 00 00 00 00 02 C4 42
		15 00 00 00 00 00 02 C5 4B
		15 00 00 00 00 00 02 C6 57
		15 00 00 00 00 00 02 C7 5B
		15 00 00 00 00 00 02 C8 66
		15 00 00 00 00 00 02 C9 DB
		15 00 00 00 00 00 02 CA DF
		15 00 00 00 00 00 02 CB F5
		15 00 00 00 00 00 02 CC FE
		15 00 00 00 00 00 02 CD FC
		15 00 00 00 00 00 02 CE F7
		15 00 00 00 00 00 02 CF F9
		15 01 00 00 00 00 02 D0 FB
		15 00 00 00 00 00 02 D1 0A
		15 00 00 00 00 00 02 D2 1F
		15 00 00 00 00 00 02 D3 40
		15 00 00 00 00 00 02 D4 4A
		15 00 00 00 00 00 02 D5 AE
		15 00 00 00 00 00 02 D6 B0
		15 00 00 00 00 00 02 D7 BB
		15 00 00 00 00 00 02 D8 C5
		15 00 00 00 00 00 02 D9 CE
		15 00 00 00 00 00 02 DA D8
		15 00 00 00 00 00 02 DB E7
		15 00 00 00 00 00 02 DC F0
		15 00 00 00 00 00 02 DD FF
		15 00 00 00 00 00 02 DE 00
		15 00 00 00 00 00 02 DF 2F
		15 00 00 00 00 00 02 E0 12
		15 00 00 00 00 00 02 E1 12
		15 00 00 00 00 00 02 E2 25
		15 00 00 00 00 00 02 E3 36
		15 00 00 00 00 00 02 E4 42
		15 00 00 00 00 00 02 E5 4B
		15 00 00 00 00 00 02 E6 57
		15 00 00 00 00 00 02 E7 5B
		15 00 00 00 00 00 02 E8 66
		15 00 00 00 00 00 02 E9 DB
		15 01 00 00 00 00 02 EA DF
		15 00 00 00 00 00 02 EB F5
		15 00 00 00 00 00 02 EC FE
		15 00 00 00 00 00 02 ED FC
		15 00 00 00 00 00 02 EE F7
		15 00 00 00 00 00 02 EF F9
		15 00 00 00 00 00 02 F0 FB
		15 00 00 00 00 00 02 F1 0A
		15 00 00 00 00 00 02 F2 1F
		15 00 00 00 00 00 02 F3 40
		15 00 00 00 00 00 02 F4 4A
		15 00 00 00 00 00 02 F5 AE
		15 00 00 00 00 00 02 F6 B0
		15 00 00 00 00 00 02 F7 BB
		15 00 00 00 00 00 02 F8 C5
		15 00 00 00 00 00 02 F9 CE
		15 00 00 00 00 00 02 FA D8
		15 00 00 00 00 00 02 FB E7
		15 00 00 00 00 00 02 FC F0
		15 00 00 00 00 00 02 FD FF
		15 00 00 00 00 00 02 FE 00
		15 01 00 00 00 00 02 FF 2F
		//----R Gamma Register----
		15 00 00 00 00 00 02 83 AA
		15 00 00 00 00 00 02 84 11
		15 00 00 00 00 00 02 C0 12
		15 00 00 00 00 00 02 C1 12
		15 00 00 00 00 00 02 C2 25
		15 00 00 00 00 00 02 C3 36
		15 00 00 00 00 00 02 C4 42
		15 00 00 00 00 00 02 C5 4B
		15 00 00 00 00 00 02 C6 57
		15 00 00 00 00 00 02 C7 5B
		15 00 00 00 00 00 02 C8 66
		15 00 00 00 00 00 02 C9 DB
		15 00 00 00 00 00 02 CA DF
		15 00 00 00 00 00 02 CB F5
		15 00 00 00 00 00 02 CC FE
		15 00 00 00 00 00 02 CD FC
		15 00 00 00 00 00 02 CE F7
		15 00 00 00 00 00 02 CF F9
		15 00 00 00 00 00 02 D0 FB
		15 01 00 00 00 00 02 D1 0A
		15 00 00 00 00 00 02 D2 1F
		15 00 00 00 00 00 02 D3 40
		15 00 00 00 00 00 02 D4 4A
		15 00 00 00 00 00 02 D5 AE
		15 00 00 00 00 00 02 D6 B0
		15 00 00 00 00 00 02 D7 BB
		15 00 00 00 00 00 02 D8 C5
		15 00 00 00 00 00 02 D9 CE
		15 00 00 00 00 00 02 DA D8
		15 00 00 00 00 00 02 DB E7
		15 01 00 00 00 00 02 DC F0
		15 00 00 00 00 00 02 DD FF
		15 00 00 00 00 00 02 DE 00
		15 00 00 00 00 00 02 DF 2F
		15 00 00 00 00 00 02 E0 12
		15 00 00 00 00 00 02 E1 12
		15 00 00 00 00 00 02 E2 25
		15 00 00 00 00 00 02 E3 36
		15 00 00 00 00 00 02 E4 42
		15 00 00 00 00 00 02 E5 4B
		15 00 00 00 00 00 02 E6 57
		15 00 00 00 00 00 02 E7 5B
		15 00 00 00 00 00 02 E8 66
		15 00 00 00 00 00 02 E9 DB
		15 00 00 00 00 00 02 EA DF
		15 00 00 00 00 00 02 EB F5
		15 00 00 00 00 00 02 EC FE
		15 00 00 00 00 00 02 ED FC
		15 00 00 00 00 00 02 EE F7
		15 00 00 00 00 00 02 EF F9
		15 00 00 00 00 00 02 F0 FB
		15 01 00 00 00 00 02 F1 0A
		15 00 00 00 00 00 02 F2 1F
		15 00 00 00 00 00 02 F3 40
		15 00 00 00 00 00 02 F4 4A
		15 00 00 00 00 00 02 F5 AE
		15 00 00 00 00 00 02 F6 B0
		15 00 00 00 00 00 02 F7 BB
		15 00 00 00 00 00 02 F8 C5
		15 00 00 00 00 00 02 F9 CE
		15 00 00 00 00 00 02 FA D8
		15 00 00 00 00 00 02 FB E7
		15 00 00 00 00 00 02 FC F0
		15 00 00 00 00 00 02 FD FF
		15 00 00 00 00 00 02 FE 00
		15 01 00 00 00 00 02 FF 2F
		];

		qcom,mdss-dsi-on-command-state = "dsi_lp_mode";
		qcom,mdss-dsi-off-command-state = "dsi_hs_mode";
		qcom,mdss-pan-physical-width-dimension = <135>;
		qcom,mdss-pan-physical-height-dimension = <216>;
		qcom,mdss-dsi-h-sync-pulse = <0>;
		qcom,mdss-dsi-traffic-mode = "non_burst_sync_event";
		qcom,mdss-dsi-lane-map = "lane_map_0123";
		qcom,mdss-dsi-bllp-eof-power-mode;
		qcom,mdss-dsi-bllp-power-mode;
		qcom,mdss-dsi-lane-0-state;
		qcom,mdss-dsi-lane-1-state;
		qcom,mdss-dsi-lane-2-state;
		qcom,mdss-dsi-lane-3-state;
		qcom,mdss-dsi-panel-timings = [F2 4B 34 00 70 82 3C 50 4A 03 04 00];
		qcom,mdss-dsi-t-clk-post = <0x02>;
		qcom,mdss-dsi-t-clk-pre = <0x31>;
		qcom,mdss-dsi-bl-min-level = <1>;
		qcom,mdss-dsi-bl-max-level = <255>;
		qcom,mdss-dsi-dma-trigger = "trigger_sw";
		qcom,mdss-dsi-mdp-trigger = "none";
		qcom,mdss-dsi-bl-pmic-control-type = "bl_others";
		qcom,off-cmds-dsi-state = "dsi_hs_mode";
	};
};

&soc {
	i2c@f9967000 {
		rt8555@31 {
			compatible = "backlight,rt8555";
			status = "disabled";
			reg = <0x31>;
			rt8555,lcd_bl_en = <&msmgpio 49 0x00>;
			rt8555,max_current = <0x92>;
			rt8555,min_brightness = <0x04>;
			rt8555,default_brightness = <0xA8>;
			rt8555,max_brightness = <0xFF>;
			rt8555,enable_pwm = <0>;
			rt8555,blmap_size = <256>;
			rt8555,blmap = <
				8 8 8 8 8 8 8 8 8 8 8 9 9 9 9
				9 9 9 9 9 9 9 9 10 10 10 10 10 10 10
				10 10 10 10 10 10 10 11 11 11 11 11 11 11 11
				11 11 11 11 12 12 12 12 12 12 12 13 13 13 13
				13 14 14 14 14 14 14 15 15 15 15 15 15 15 16
				16 16 16 16 17 17 17 17 17 18 18 18 18 18 18
				19 19 19 19 19 20 20 21 21 22 23 23 24 25 25
				26 27 28 28 29 29 30 31 31 32 32 33 34 34 35
				36 36 37 37 38 38 39 39 40 40 41 41 42 42 42
				43 43 44 45 47 48 50 51 52 54 55 57 58 59 61
				62 64 66 67 68 69 70 71 73 74 75 77 78 79 80
				81 82 83 84 84 85 86 86 87 87 87 89 90 92 94
				97 99 101 103 104 105 107 108 110 112 113 115 117 119 121
				122 124 125 127 129 131 133 134 136 138 139 141 143 145 147
				149 151 153 155 157 157 159 162 164 166 169 171 173 175 177
				180 182 184 187 189 191 193 196 198 200 202 204 207 209 211
				214 216 219 222 225 227 229 231 234 237 240 243 246 249 252
				255>;
		};
	};
};
